# ATtiny3217 device description
Architecture: AVR8X; Family: AVR TINY
Registers are 8-bit, read-write, reset 0x0 unless marked. A register's access mark holds for its fields unless they carry their own. Offsets are from the block's base; [hi:lo] are bit positions; 'fields as' and 'values as' point back to an identical list.

## BOD — Bod interface
Instances: BOD 0x0080
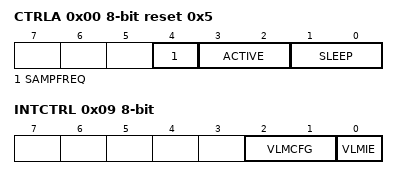
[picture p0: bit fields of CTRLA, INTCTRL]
0x00 CTRLA reset 0x5 — Control A
  [4] SAMPFREQ ro — Sample frequency
    0=1KHZ (1kHz sampling frequency); 1=125HZ (125Hz sampling frequency)
  [3:2] ACTIVE ro — Operation in active mode
    0=DIS (Disabled); 1=ENABLED; 2=SAMPLED; 3=ENWAKE (Enabled with wake-up halted until BOD is ready)
  [1:0] SLEEP — Operation in sleep mode
    0=DIS (Disabled); 1=ENABLED; 2=SAMPLED
0x01 CTRLB — Control B
  [2:0] LVL ro — Bod level
    0=BODLEVEL0 (1.8 V); 2=BODLEVEL2 (2.6 V); 7=BODLEVEL7 (4.2 V)
0x08 VLMCTRLA — Voltage level monitor Control
  [1:0] VLMLVL — voltage level monitor level
    0=5ABOVE (VLM threshold 5% above BOD level); 1=15ABOVE (VLM threshold 15% above BOD level); 2=25ABOVE (VLM threshold 25% above BOD level)
0x09 INTCTRL — Voltage level monitor interrupt Control
  [2:1] VLMCFG — Configuration
    0=BELOW (Interrupt when supply goes below VLM level); 1=ABOVE (Interrupt when supply goes above VLM level); 2=CROSS (Interrupt when supply crosses VLM level)
  [0] VLMIE — voltage level monitor interrrupt enable
0x0A INTFLAGS — Voltage level monitor interrupt Flags
  [0] VLMIF — Voltage level monitor interrupt flag
0x0B STATUS — Voltage level monitor status
  [0] VLMS ro

## CCL — Configurable Custom Logic
Instances: CCL 0x01C0
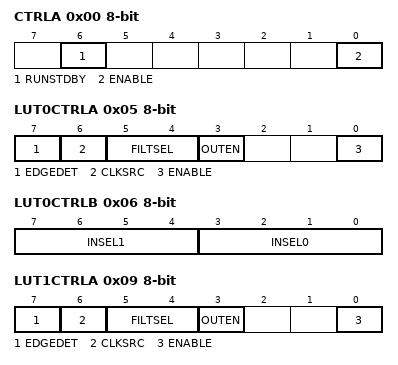
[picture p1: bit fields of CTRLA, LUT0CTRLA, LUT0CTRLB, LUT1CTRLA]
0x00 CTRLA — Control Register A
  [6] RUNSTDBY — Run in Standby
  [0] ENABLE
0x01 SEQCTRL0 — Sequential Control 0
  [2:0] SEQSEL — Sequential Selection
    0=DISABLE (Sequential logic disabled); 1=DFF (D FlipFlop); 2=JK (JK FlipFlop); 3=LATCH (D Latch); 4=RS (RS Latch)
0x05 LUT0CTRLA — LUT Control 0 A
  [7] EDGEDET — Edge Detection Enable
    0=DIS (Edge detector is disabled); 1=EN (Edge detector is enabled)
  [6] CLKSRC — Clock Source Selection
  [5:4] FILTSEL — Filter Selection
    0=DISABLE (Filter disabled); 1=SYNCH (Synchronizer enabled); 2=FILTER (Filter enabled)
  [3] OUTEN — Output Enable
  [0] ENABLE — LUT Enable
0x06 LUT0CTRLB — LUT Control 0 B
  [7:4] INSEL1 — LUT Input 1 Source Selection
    0=MASK (Masked input); 1=FEEDBACK (Feedback input source); 2=LINK (Linked LUT input source); 3=EVENT0 (Event input source 0); 4=EVENT1 (Event input source 1); 5=IO (IO pin LUTn-N1 input source); 6=AC0 (AC0 OUT input source); 7=TCB0 (TCB0 WO input source); 8=TCA0 (TCA0 WO1 input source); 9=TCD0 (TCD0 WOB input source); 10=USART0 (USART0 TXD input source); 11=SPI0 (SPI0 MOSI input source); 12=AC1 (AC1 OUT input source); 13=TCB1 (TCB1 WO input source); 14=AC2 (AC2 OUT input source)
  [3:0] INSEL0 — LUT Input 0 Source Selection
    0=MASK (Masked input); 1=FEEDBACK (Feedback input source); 2=LINK (Linked LUT input source); 3=EVENT0 (Event input source 0); 4=EVENT1 (Event input source 1); 5=IO (IO pin LUTn-IN0 input source); 6=AC0 (AC0 OUT input source); 7=TCB0 (TCB0 WO input source); 8=TCA0 (TCA0 WO0 input source); 9=TCD0 (TCD0 WOA input source); 10=USART0 (USART0 XCK input source); 11=SPI0 (SPI0 SCK source); 12=AC1 (AC1 OUT input source); 13=TCB1 (TCB1 WO input source); 14=AC2 (AC2 OUT input source)
0x07 LUT0CTRLC — LUT Control 0 C
  [3:0] INSEL2 — LUT Input 2 Source Selection
    0=MASK (Masked input); 1=FEEDBACK (Feedback input source); 2=LINK (Linked LUT input source); 3=EVENT0 (Event input source 0); 4=EVENT1 (Event input source 1); 5=IO (IO pin LUTn-IN2 input source); 6=AC0 (AC0 OUT input source); 7=TCB0 (TCB0 WO input source); 8=TCA0 (TCA0 WO2 input source); 9=TCD0 (TCD0 WOA input source); 11=SPI0 (SPI0 MISO source); 12=AC1 (AC1 OUT input source); 13=TCB1 (TCB1 WO input source); 14=AC2 (AC2 OUT input source)
0x08 TRUTH0 reset not defined
0x09 LUT1CTRLA — LUT Control 1 A
  fields as LUT0CTRLA
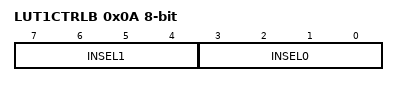
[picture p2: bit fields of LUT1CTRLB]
0x0A LUT1CTRLB — LUT Control 1 B
  fields as LUT0CTRLB
0x0B LUT1CTRLC — LUT Control 1 C
  fields as LUT0CTRLC
0x0C TRUTH1 reset not defined
